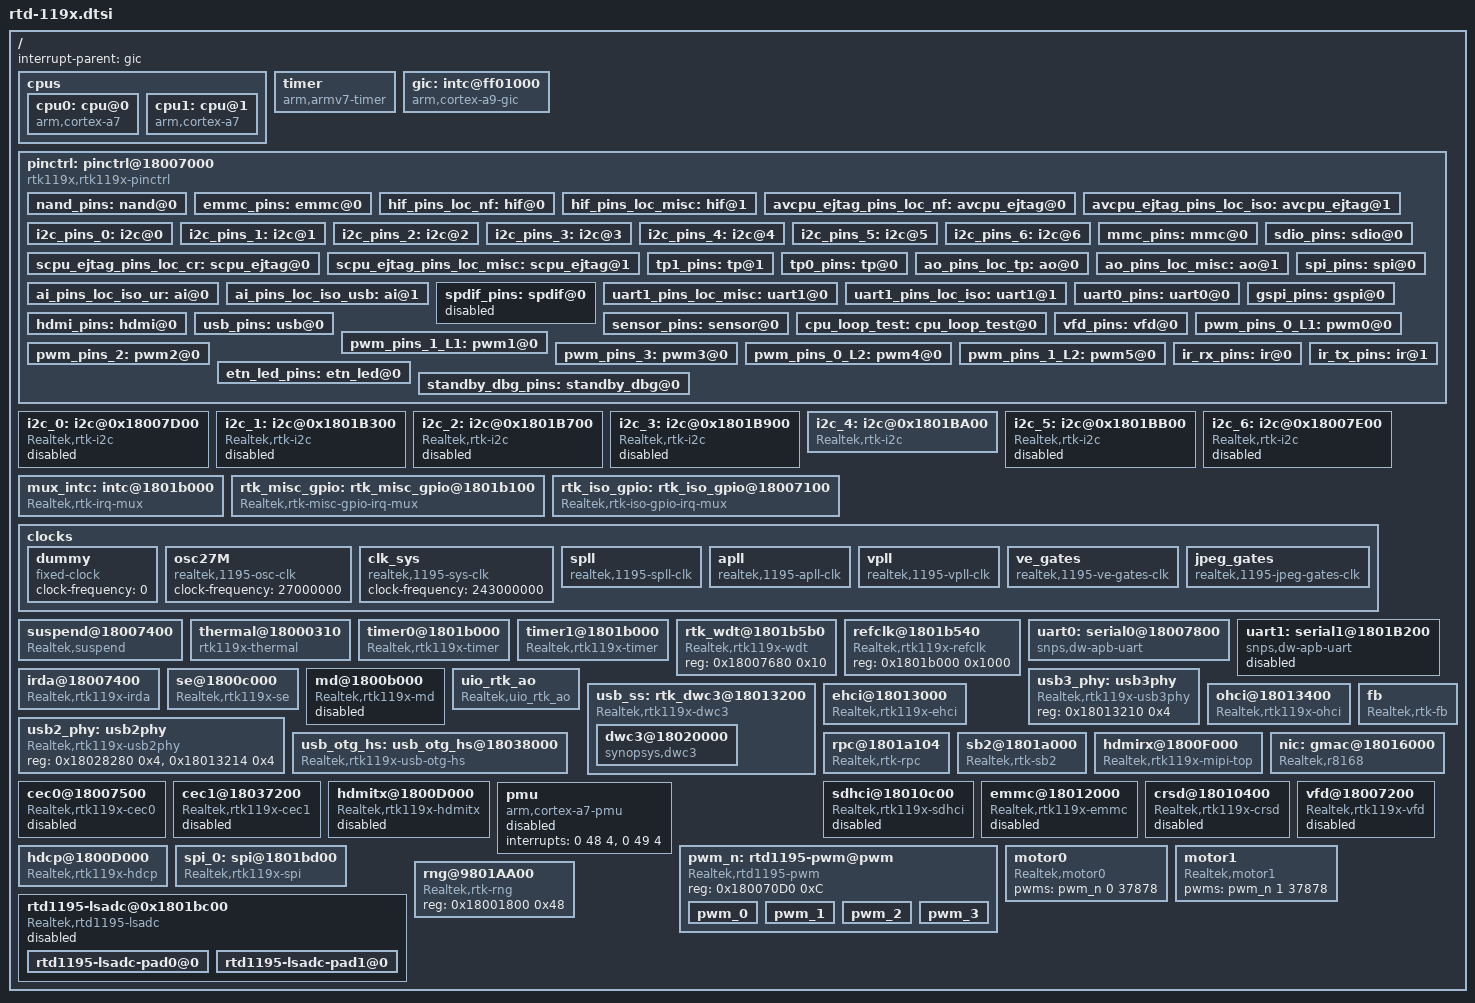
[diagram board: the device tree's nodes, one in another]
/include/ "skeleton.dtsi"
/include/ "rtd-119x-dvfs.dtsi"


/ {
	interrupt-parent = <&gic>;
	#address-cells = <1>;
	#size-cells = <1>;

	cpus {
		#address-cells = <1>;
		#size-cells = <0>;

		cpu0: cpu@0 {
			device_type = "cpu";
			compatible = "arm,cortex-a7";
			reg = <0x0>;
			clock-frequency = <1000000000>;
		};
		cpu1: cpu@1 {
			device_type = "cpu";
			compatible = "arm,cortex-a7";
			reg = <0x1>;
			clock-frequency = <1000000000>;
		};
	};
	timer {
		compatible = "arm,armv7-timer";
		interrupts = <1 13 0xf08>,			/* secure */
			     <1 14 0xf08>;				/* non-secure */
//			     <1 11 0xf08>,				/* virtual */
//			     <1 10 0xf08>;				/* hypervisor */
		clock-frequency = <27000000>;
	};
	gic: intc@ff01000 {
		compatible = "arm,cortex-a9-gic";
		#interrupt-cells = <3>;
		interrupt-controller;
		reg = <0xff011000 0x1000>,
		      <0xff012000 0x1000>;
	};

	pinctrl: pinctrl@18007000 {
		compatible = "rtk119x,rtk119x-pinctrl";
		reg = <0x018000000 0x500>, <0x18007000 0x400>;
		#gpio-range-cells = <3>;

		pinctrl-names = "default";
		pinctrl-0 = <&uart1_pins_loc_iso>,<&mmc_pins>,<&pwm_pins_0_L2>,<&pwm_pins_1_L2>,<&i2c_pins_4>;

		nand_pins: nand@0 {
			rtk119x,pins =
			"nf_dd_0", 	"nf_dd_1",	"nf_dd_2", 	"nf_dd_3",	"nf_dd_4", 	"nf_dd_5",
			"nf_dd_6", 	"nf_dd_7",	"nf_rdy", 		"nf_rd_n",	"nf_wr_n", 	"nf_ale",
			"nf_cle", 		"nf_ce_n_0",	"nf_ce_n_1", 	"i2c_scl_5",	"i2c_sda_5";
			rtk119x,function = "nand";
			rtk119x,pull_en = <0>;
		};
		emmc_pins: emmc@0 {
			rtk119x,pins=
			"nf_dd_0", 	"nf_dd_1",	"nf_dd_2", 	"nf_dd_3",	"nf_dd_4", 	"nf_dd_5",
			"nf_dd_6", 	"nf_dd_7",	"nf_rdy", 		"nf_rd_n",	"nf_cle";
			rtk119x,function = "emmc";
			rtk119x,pull_en = <0>;
		};
		hif_pins_loc_nf: hif@0 {
			rtk119x,pins =
			"nf_dd_4", 	"nf_wr_n",	"nf_ale", 		"nf_cle", 		"hi_loc";
			rtk119x,function = "hif_loc_nf";
			rtk119x,pull_en = <0>;
		};
		hif_pins_loc_misc: hif@1 {
			rtk119x,pins =
			"gpio_0", 	"gpio_1"	,	"gpio_2", 	"gpio_3", 	"hi_loc",	"sf_en";
			rtk119x,function = "hif_loc_misc";
			rtk119x,pull_en = <0>;
		};
		avcpu_ejtag_pins_loc_nf: avcpu_ejtag@0 {
			rtk119x,pins =
			"nf_dd_5", 	"nf_dd_6",	"nf_dd_7", 	"nf_rdy",		"nf_rd_n",	"ejtag_avcpu_loc";
			rtk119x,function = "avcpu_ejtag_loc_nf";
			rtk119x,pull_en = <0>;
		};
		avcpu_ejtag_pins_loc_iso: avcpu_ejtag@1 {
			rtk119x,pins =
			"usb0", 		"usb1",		"vfd_cs_n", 	"vfd_clk",		"vfd_d",		"ejtag_avcpu_loc";
			rtk119x,function = "avcpu_ejtag_loc_iso";
			rtk119x,pull_en = <0>;
		};
		i2c_pins_0: i2c@0 {
			rtk119x,pins =
			"i2c_scl_0", "i2c_sda_0";
			rtk119x,function = "i2c0";
			rtk119x,pull_en = <0>;

//			rtk119x,schmitt = <1>;		//0: schmitt_disable, 1:schmitt_enable
//			rtk119x,drive = <4>;		//drive current : 2=2mA  4=4mA 8=8mA
//			rtk119x,pull_en = <1>;		//0: pull_disable, 1:pull_enable
//			rtk119x,pull_sel = <1>;		//0: pull_low, 1:pull_high
		};
		i2c_pins_1: i2c@1 {
			rtk119x,pins =
			"i2c_scl_1", 	"i2c_sda_1";
			rtk119x,function = "i2c1";
			rtk119x,pull_en = <0>;
		};
		i2c_pins_2: i2c@2 {
			rtk119x,pins =
			"tp1_clk",		"tp1_sync",	"vfd_d";
			rtk119x,function = "i2c2";
			rtk119x,pull_en = <0>;
		};
		i2c_pins_3: i2c@3 {
			rtk119x,pins =
			"tp1_data", 	"tp1_valid";
			rtk119x,function = "i2c3";
			rtk119x,pull_en = <0>;
		};
		i2c_pins_4: i2c@4 {
			rtk119x,pins =
			"i2c_scl_4", 	"i2c_sda_4";
			rtk119x,function = "i2c4";
			rtk119x,pull_en = <0>;
		};
		i2c_pins_5: i2c@5 {
			rtk119x,pins =
			"i2c_scl_5",	"i2c_sda_5";
			rtk119x,function = "i2c5";
			rtk119x,pull_en = <0>;

//			rtk119x,schmitt = <1>;		//0: schmitt_disable, 1:schmitt_enable
//			rtk119x,drive = <2>;		//drive current : 2=2mA  4=4mA 8=8mA
//			rtk119x,pull_en = <1>;		//0: pull_disable, 1:pull_enable
//			rtk119x,pull_sel = <1>;		//0: pull_low, 1:pull_high
		};
		i2c_pins_6: i2c@6 {
			rtk119x,pins =
			"i2c_scl_6",	"i2c_sda_6";
			rtk119x,function = "i2c6";
			rtk119x,pull_en = <0>;
		};
		mmc_pins: mmc@0 {
			rtk119x,pins =
			"mmc_data_0", 	"mmc_data_1",	"mmc_data_2", 	"mmc_data_3",	"mmc_clk", 	"mmc_cmd",
			"mmc_wp", 		"mmc_cd";
			rtk119x,function = "mmc";
			rtk119x,pull_en = <0>;
		};
		scpu_ejtag_pins_loc_cr: scpu_ejtag@0 {
			rtk119x,pins =
			"mmc_data_0", 	"mmc_data_3",	"mmc_clk", 	"mmc_cmd",	"mmc_wp",	"ejtag_scpu_loc";
			rtk119x,function = "scpu_ejtag_loc_cr";
			rtk119x,pull_en = <0>;
		};
		scpu_ejtag_pins_loc_misc: scpu_ejtag@1 {
			rtk119x,pins =
			"gpio_4", 		"gpio_5",			"gpio_6", 	"gpio_7",		"gpio_8",		"ejtag_scpu_loc";
			rtk119x,function = "scpu_ejtag_loc_misc";
			rtk119x,pull_en = <0>;
		};
		sdio_pins: sdio@0 {
			rtk119x,pins =
			"sdio_clk", 	"sdio_data_0",		"sdio_data_1", 	"sdio_data_2",		"sdio_data_3", 	"sdio_cmd";
			rtk119x,function = "sdio";
			rtk119x,pull_en = <0>;
		};
		tp1_pins: tp@1 {
			rtk119x,pins =
			"tp1_data", 	"tp1_clk",		"tp1_valid", 	"tp1_sync";
			rtk119x,function = "tp1";
			rtk119x,pull_en = <0>;
		};
		tp0_pins: tp@0 {
			rtk119x,pins =
			"tp0_data", 	"tp0_clk",		"tp0_valid", 	"tp0_sync";
			rtk119x,function = "tp0";
			rtk119x,pull_en = <0>;
		};
		ao_pins_loc_tp: ao@0 {
			rtk119x,pins =
			"tp0_data", 	"tp0_clk",		"tp0_valid", 	"tp0_sync",	"ao_loc";
			rtk119x,function = "ao_loc_tp";
			rtk119x,pull_en = <0>;
		};
		ao_pins_loc_misc: ao@1 {
			rtk119x,pins =
			"gpio_4", 	"gpio_5",		"gpio_6", 	"gpio_7",		"ao_loc";
			rtk119x,function = "ao_loc_misc";
			rtk119x,pull_en = <0>;
		};
		ai_pins_loc_iso_ur: ai@0 {
			rtk119x,pins =
			"ur1_rx", 	"ur1_tx",		"ur1_cts_n", 	"ur1_rts_n",	"ai_loc";
			rtk119x,function = "ai_loc_iso_ur";
			rtk119x,pull_en = <0>;
		};
		ai_pins_loc_iso_usb: ai@1 {
			rtk119x,pins =
			"usb0", 		"usb1",		"vfd_cs_n", 	"vfd_clk",		"ai_loc";
			rtk119x,function = "ai_loc_iso_usb";
			rtk119x,pull_en = <0>;
		};

		spdif_pins: spdif@0 {
			rtk119x,pins =
			"spdif";
			rtk119x,function = "spdif";
			rtk119x,pull_en = <0>;
			status = "disabled";
		};
		spi_pins: spi@0 {
			rtk119x,pins =
			"gpio_0", 	"gpio_1"	,	"gpio_2", 	"gpio_3",		"sf_en";
			rtk119x,function = "spi";
			rtk119x,pull_en = <0>;
		};
		uart1_pins_loc_misc: uart1@0 {
			rtk119x,pins =
			"gpio_0", 	"gpio_1"	,	"gpio_2", 	"gpio_3",		"ur1_loc",	"sf_en";
			rtk119x,function = "uart1_loc_misc";
			rtk119x,pull_en = <0>;
		};
		uart1_pins_loc_iso: uart1@1 {
			rtk119x,pins =
			"ur1_rx", 	"ur1_tx",		"ur1_cts_n", 	"ur1_rts_n",	"ur1_loc";
			rtk119x,function = "uart1_loc_iso";
			rtk119x,pull_en = <0>;
		};
		uart0_pins: uart0@0 {
			rtk119x,pins =
			"ur0_rx", 	"ur0_tx";
			rtk119x,function = "uart0";
			rtk119x,pull_en = <0>;
		};
		gspi_pins: gspi@0 {
			rtk119x,pins =
			"gpio_0", 	"gpio_1"	,	"gpio_2", 	"gpio_3",		"sf_en";
			rtk119x,function = "gspi";
			rtk119x,pull_en = <0>;
		};
		hdmi_pins: hdmi@0 {
			rtk119x,pins =
			"hdmi_hpd";
			rtk119x,function = "hdmi";
			rtk119x,pull_en = <0>;
		};
		usb_pins: usb@0 {
			rtk119x,pins=
			"usb_id";
			rtk119x,function = "usb";
			rtk119x,pull_en = <0>;
		};
		sensor_pins: sensor@0 {
			rtk119x,pins =
			"sensor_cko_0", 	"sensor_cko_",	"sensor_rst", 		"sensor_stb_0",	"sensor_stb_1";
			rtk119x,function = "sensor";
			rtk119x,pull_en = <0>;
		};
		cpu_loop_test: cpu_loop_test@0 {
			rtk119x,pins=
			"usb_id";
			rtk119x,function = "cpu_loop";
			rtk119x,pull_en = <0>;
		};
		vfd_pins: vfd@0 {
			rtk119x,pins =
			"vfd_cs_n", 	"vfd_clk",		"vfd_d";
			rtk119x,function = "vfd";
			rtk119x,pull_en = <0>;
		};
		pwm_pins_0_L1: pwm0@0 {
			rtk119x,pins =
			"ur1_rx";
			rtk119x,function = "pwm";
			rtk119x,pull_en = <0>;
		};
		pwm_pins_1_L1: pwm1@0 {
			rtk119x,pins =
			"ur1_tx";
			rtk119x,function = "pwm";
			rtk119x,pull_en = <0>;
		};
		pwm_pins_2: pwm2@0 {
			rtk119x,pins =
			"ur0_tx";
			rtk119x,function = "pwm";
			rtk119x,pull_en = <0>;
		};
		pwm_pins_3: pwm3@0 {
			rtk119x,pins =
			"ur0_rx";
			rtk119x,function = "pwm";
			rtk119x,pull_en = <0>;
		};
		pwm_pins_0_L2: pwm4@0 {
			rtk119x,pins =
			"etn_led_link";
			rtk119x,function = "pwm";
			rtk119x,pull_en = <0>;
		};
		pwm_pins_1_L2: pwm5@0 {
			rtk119x,pins =
			"etn_led_rxtx";
			rtk119x,function = "pwm";
			rtk119x,pull_en = <0>;
		};
		ir_rx_pins: ir@0 {
			rtk119x,pins =
			"ir_rx";
			rtk119x,function = "irrx";
			rtk119x,pull_en = <0>;
		};
		ir_tx_pins: ir@1 {
			rtk119x,pins =
			"ir_tx";
			rtk119x,function = "irtx";
			rtk119x,pull_en = <0>;
		};
		etn_led_pins: etn_led@0 {
			rtk119x,pins =
			"etn_led_link", 	"etn_led_rxtx";
			rtk119x,function = "etn_led";
			rtk119x,pull_en = <0>;
		};
		standby_dbg_pins: standby_dbg@0 {
			rtk119x,pins =
			"usb0",	"usb1",   "ir_rx";
			rtk119x,function = "standby_dbg";
			rtk119x,pull_en = <0>;
		};
	};

i2c_0: i2c@0x18007D00 {
		compatible = "Realtek,rtk-i2c";
		reg = <0x18007D00 0x400>;
		interrupt-parent = <&mux_intc>;
		interrupts = <1 8>;
		i2c-num = <0>;
		#address-cells = <1>;
		#size-cells = <0>;
		status = "dis";
	};
	i2c_1: i2c@0x1801B300 {
		compatible = "Realtek,rtk-i2c";
		reg = <0x1801B300 0x400>;
		interrupt-parent = <&mux_intc>;
		interrupts = <0 4>;
		i2c-num = <1>;
		#address-cells = <1>;
		#size-cells = <0>;
		status = "dis";
	};
	i2c_2: i2c@0x1801B700 {
		compatible = "Realtek,rtk-i2c";
		#address-cells = <1>;
		#size-cells = <0>;
		reg = <0x1801B700 0x400>;
		interrupt-parent = <&mux_intc>;
		interrupts = <0 26>;
		i2c-num = <2>;
		status = "dis";
	};
	i2c_3: i2c@0x1801B900 {
		compatible = "Realtek,rtk-i2c";
		reg = <0x1801B900 0x400>;
		interrupt-parent = <&mux_intc>;
		interrupts = <0 23>;
		i2c-num = <3>;
		#address-cells = <1>;
		#size-cells = <0>;
		status = "dis";
	};
	i2c_4: i2c@0x1801BA00 {
		compatible = "Realtek,rtk-i2c";
		reg = <0x1801BA00 0x400>;
		interrupt-parent = <&mux_intc>;
		interrupts = <0 15>;
		i2c-num = <4>;
		#address-cells = <1>;
		#size-cells = <0>;
	};
	i2c_5: i2c@0x1801BB00 {
		compatible = "Realtek,rtk-i2c";
		reg = <0x1801BB00 0x400>;
		interrupt-parent = <&mux_intc>;
		interrupts = <0 14>;
		i2c-num = <5>;
		#address-cells = <1>;
		#size-cells = <0>;
		status = "dis";
	};
	i2c_6: i2c@0x18007E00 {
		compatible = "Realtek,rtk-i2c";
		reg = <0x18007E00 0x400>;
		interrupt-parent = <&mux_intc>;
		interrupts = <1 10>;
		i2c-num = <6>;
		#address-cells = <1>;
		#size-cells = <0>;
		status = "dis";
	};

	mux_intc: intc@1801b000 {
		compatible = "Realtek,rtk-irq-mux";
		Realtek,mux-nr = <2>;
		#interrupt-cells = <2>;
		interrupt-controller;
		reg = <0x1801b000 0x100>, <0x18007000 0x100>;		/* MISC_TOP MISC_ISO */
		interrupts = <0 40 4>, <0 41 4>;
		intr-status = <0xc>, <0x0>;
		intr-en = <0x80>, <0x40>;
	};

	rtk_misc_gpio: rtk_misc_gpio@1801b100 {
		compatible = "Realtek,rtk-misc-gpio-irq-mux";
		gpio-controller;
		#gpio-cells = <3>;								/*must be the same with gpiochip.of_gpio_n_cells*/
		Realtek,gpio_base = <0>;
		Realtek,gpio_numbers = <60>;
		interrupt-parent = <&mux_intc>;
		#interrupt-cells = <1>;
		interrupt-controller;
		interrupts = <0 19>, <0 20>;						/*GPIOA_INT   GPIODA_INT*/
		reg = <0x1801b000 0x100>, <0x1801b100 0x100>;		/* MISC_SYS MISC_GPIO*/
		gpio-ranges = <&pinctrl 0 0 60>;
	};


	rtk_iso_gpio: rtk_iso_gpio@18007100 {
		compatible = "Realtek,rtk-iso-gpio-irq-mux";
		gpio-controller;
		#gpio-cells = <3>;
		Realtek,gpio_base = <60>;
		Realtek,gpio_numbers = <21>;
		interrupt-parent = <&mux_intc>;
		#interrupt-cells = <1>;
		interrupt-controller;
		interrupts = <1 19>, <1 20>;						/*GPIOA_INT   GPIODA_INT*/
		reg = <0x18007000 0x100>, <0x18007100 0x100>;		/* ISO_SYS ISO_GPIO*/
		gpio-ranges = <&pinctrl 0 64 21>;
	};

	clocks {
		#address-cells = <1>;
		#size-cells = <1>;
		ranges;

		/*
		 * This is a dummy clock, to be used as placeholder on
		 * other mux clocks when a specific parent clock is not
		 * yet implemented. It should be dropped when the driver
		 * is complete.
		 */
		dummy: dummy {
			compatible = "fixed-clock";
			#clock-cells = <0>;
			clock-frequency = <0>;
		};

		//osc33m: osc33m {
		//	compatible = "fixed-clock";
		//	#clock-cells = <0>;
		//	clock-frequency = <33000000>;
		//};

        osc27M: osc27M {
            compatible = "realtek,1195-osc-clk";
            #clock-cells = <0>;
            clock-frequency = <27000000>;
        };

        clk_sys: clk_sys {
            compatible = "realtek,1195-sys-clk";
            #clock-cells = <0>;
            clock-frequency = <243000000>;
        };

        spll: spll { // freq = osc * (n + 1 + f/2048) / (0x1 << d)
            compatible = "realtek,1195-spll-clk";
            #clock-cells = <0>;
            clocks      = <&osc27M>;
            reg         = <0x18000000 0x134>;
            //n-max        = <>;
            n-min        = <0>;
            //f-max        = <>;
            f-min        = <0>;
            //d-max        = <0>;
            d-min        = <0>;
            pll-max-frequency = <3000000000>; // 3GHz
            pll-min-frequency = <200000000>; // 200MHz
            clock-names = "scpu";
        };

        apll: apll { // freq = osc * (n + 2) / (f + 1) / (d + 1)
            compatible = "realtek,1195-apll-clk";
            #clock-cells = <0>;
            clocks       = <&osc27M>;
            reg          = <0x1800010c 0x8>;
            //n-max        = <>;
            n-min        = <0>;
            //f-max        = <0>;
            f-min        = <0>;
            d-max        = <0>;
            d-min        = <0>;
            pll-max-frequency = <1000000000>; // 1GHz
            pll-min-frequency = <50000000>; // 50MHz
            clock-names = "acpu";
        };

        vpll: vpll { // freq = osc * (n + 2) / (f + 1) / (d + 1)
            compatible = "realtek,1195-vpll-clk";
            #clock-cells = <0>;
            clocks       = <&osc27M>;
            reg          = <0x18000114 0x8>;
            //n-max        = <>;
            n-min        = <0>;
            f-max        = <0>;
            f-min        = <0>;
            //d-max        = <0>;
            d-min        = <0>;
            pll-max-frequency = <1000000000>; // 1GHz
            pll-min-frequency = <0>;
            clock-names = "ve";
        };

        ve_gates: ve_gates {
            #clock-cells = <1>;
            compatible = "realtek,1195-ve-gates-clk";
            reg = <0x1800000c 0x4>;
            clocks = <&vpll>;
            clock-output-names = "h265","h264";
        };

        jpeg_gates: jpeg_gates {
            compatible = "realtek,1195-jpeg-gates-clk";
            #clock-cells = <1>;
            reg = <0x1800000c 0x4>;
            clocks = <&clk_sys>;
            clock-output-names = "jpeg";
        };
	};

    suspend@18007400 {
        compatible = "Realtek,suspend";
        suspend-mode = <0>; // 0:SUSPEND_TO_RAM 1:SUSPEND_TO_COOLBOOT 2:SUSPEND_TO_WFI
        reg-restore = <0x18000000 0x18000004 0x18000008 0x1800000c 0x18000010>;
        reg-restore-size = <5>;
    };

    thermal@18000310 {
        compatible = "rtk119x-thermal";
        reg = <0x180171C8 0x4>, <0x18000310 0x4>, <0x18000314 0x4>;
        thermal0-disable = <0>;
        thermal1-disable = <0>;
        thermal-polling-ms = <500>;
        thermal-trip-shutdown = <0>;
        thermal-trend-urgent = <0>;
        thermal-table = <
            105     800000
            >; // temperature(degree Celsius) frequency(kHz)

        status = "okay";
    };

	timer0@1801b000 {
		compatible = "Realtek,rtk119x-timer";
		reg = <0x1801b000 0x600>;
		interrupts = <0 17 4>;
		/* This value must be overriden by the board. */
		clock-frequency = <0>;
	};
	timer1@1801b000 {
		compatible = "Realtek,rtk119x-timer";
		reg = <0x1801b000 0x600>;
		interrupts = <0 18 4>;
		/* This value must be overriden by the board. */
		clock-frequency = <0>;
	};
	rtk_wdt@1801b5b0 {
		compatible = "Realtek,rtk119x-wdt";
		reg = <0x18007680 0x10>;
	};

    refclk@1801b540 {
        compatible = "Realtek,rtk119x-refclk";
        reg = <0x1801b000 0x1000>;
    };

	uart0: serial0@18007800 {
		compatible = "snps,dw-apb-uart";
		interrupt-parent = <&mux_intc>;
		reg = <0x18007800 0x400>, <0x18007000 0x100>;
        interrupts-st-mask = <0x4>;
		interrupts = <1 2>;
		reg-shift = <2>;
		reg-io-width = <4>;
		/* This value must be overriden by the board. */
		clock-frequency = <0>;
	};
	uart1: serial1@1801B200 {
		compatible = "snps,dw-apb-uart";
		interrupt-parent = <&mux_intc>;
		reg = <0x1801B200 0x100>, <0x1801b00c 0x100>;
        interrupts-st-mask = <0x8>;
		interrupts = <0 3>, <0 5>;	/*UR1_INT and UR1_TO_INT*/
		reg-shift = <2>;
		reg-io-width = <4>;
		/* This value must be overriden by the board. */
		clock-frequency = <0>;
		status = "dis";
	};

	irda@18007400 {
		compatible = "Realtek,rtk119x-irda";
		interrupt-parent = <&mux_intc>;
		reg = <0x18007000 0x400>, <0x18007400 0x100>;
		interrupts = <1 5>;
//		pinctrl-names = "default";
//		pinctrl-0 = <&i2c_pins_5>;
//		status = "default";
//		gpios = <&rtk_iso_gpio 7>;
	};

	se@1800c000 {
		compatible = "Realtek,rtk119x-se";
		reg = <0x1800c000 0x600>;
		interrupts = <0 20 4>;
	};
	md@1800b000 {
		compatible = "Realtek,rtk119x-md";
		reg = <0x1800b000 0x100>;
		interrupts = <0 38 4>;
		status = "dis";
	};

	uio_rtk_ao {
		compatible = "Realtek,uio_rtk_ao";
		reg = <0x18000000 0x1000>, <0x18006000 0x1000>, <0x1800D000 0x1000>, <0x18071200 0x1000>;
	};

	usb_ss: rtk_dwc3@18013200 {
		compatible = "Realtek,rtk119x-dwc3";
		reg = <0x18013200 0x200>;
		interrupts = <0 21 4>;
		#address-cells = <1>;
		#size-cells = <1>;
		ranges;
		dwc3@18020000 {
			compatible = "synopsys,dwc3";
			reg = <0x18020000 0x9000>;
			interrupts = <0 21 4>;
			usb-phy = <&usb2_phy &usb3_phy>;
			dr_mode = "host";		/* peripheral */
//			tx-fifo-resize;
		};
	};
	usb3_phy: usb3phy {
		compatible = "Realtek,rtk119x-usb3phy";
		reg = <0x18013210 0x4>;
		#address-cells = <1>;
		#size-cells = <1>;
		ranges;
	};
	usb2_phy: usb2phy {
		compatible = "Realtek,rtk119x-usb2phy";
		reg = <0x18028280 0x4>, <0x18013214 0x4>;
		#address-cells = <1>;
		#size-cells = <1>;
		ranges;
	};
	ehci@18013000 {
		compatible = "Realtek,rtk119x-ehci";
		reg = <0x18013000 0x400>;
		interrupts = <0 21 4>;
	};
	ohci@18013400 {
		compatible = "Realtek,rtk119x-ohci";
		reg = <0x18013400 0x400>;
		interrupts = <0 21 4>;
	};
	usb_otg_hs: usb_otg_hs@18038000 {
		compatible = "Realtek,rtk119x-usb-otg-hs";
		reg = <0x18038000 0x8000>;
		interrupts = <0 21 4>;
	};

	fb {
		compatible = "Realtek,rtk-fb";
		reg = <0x1E800000 0x1800000>;
		resolution = <1280 720>;
		fps = <60>;
	};
	rpc@1801a104 {
		compatible = "Realtek,rtk-rpc";
		reg = <0x1801a104 0xc>;
		interrupts = <0 33 4>;
	};
	sb2@1801a000 {
		compatible = "Realtek,rtk-sb2";
		reg = <0x1801a000 0x900>;
		interrupts = <0 36 4>;
	};
	hdmirx@1800F000 {
		compatible = "Realtek,rtk119x-mipi-top";
		reg = <0x1800F000 0x418>,<0x1800FB00 0x100>,<0x18037200 0xDC>,<0x18037300 0x14>,<0x1800F600 0x1c>,<0x18037400 0x40>,<0x1800F000 0x200>,<0x1800F200 0x60>,<0x1800F260 0xA0>,<0x1800F300 0xC0>,<0x1800F3C0 0x20>,<0x1800F3E0 0x10>,<0x1800d1b0 0x10>,<0x18037700 0x98>,<0x18037600 0x98>,<0x18004100 0x100>,<0x18004000 0xf0>,<0x1800FF00 0x28>, <0x1800FD00 0x50>;
		interrupts = <0 23 4>;
		mipi_input_type = <0>;/* 0:camera in ;1:HDMI_RX in */
		mipi_camera_type = <5>; /* 1:MIPI_CAMERA_RLE0551C; 2:MIPI_CAMERA_RTS5845; 3:MIPI_CAMERA_OV5645 4:MIPI_CAMERA_OV5647 5:MIPI_CAMERA_OV9782*/
		power-saving = <0>; /* 1:ON,0:OFF; Turn off RX when cable unplugged */
	};
	nic: gmac@18016000 {
		compatible = "Realtek,r8168";
		reg = <0x18016000 0x1000>;
		interrupts = <0 22 4>;
		rtl-config = <1>;
		mac-version = <42>;		/* RTL_GIGA_MAC_VER_42 */
		rtl-features = <2>;		/* BIT(2) GMii */
	};
	cec0@18007500 {
		compatible = "Realtek,rtk119x-cec0";
		interrupt-parent = <&mux_intc>;
		reg = <0x18007500 0xe0>,<0x18007040 0xa>;
		interrupts = <1 22>;
		module-enable = <0>;
		status = "disabled";
	};
	cec1@18037200 {
	    compatible = "Realtek,rtk119x-cec1";
	    reg = <0x18037200 0xf0>,<0x18007000 0xF00>,<0x18037500 0x10>;
		interrupts = <0 34 4>;
		module-enable = <1>;
	    status = "disabled";
    };
	hdmitx@1800D000 {
		compatible = "Realtek,rtk119x-hdmitx";
		reg = <0x1800d000 0x400>;
		gpios = <&rtk_iso_gpio 6 0 0>;          /*HPD, input, default N/A */
		interrupt-parent = <&rtk_iso_gpio>;
		interrupts = <6>;                       /*HPD*/
		status = "disabled";
	};
	sdhci@18010c00 {
		compatible = "Realtek,rtk119x-sdhci";
		reg = <0x18010c00 0x100>,<0x18000000 0x50>;
		interrupts = <0 45 4>;
		status = "dis";
	};
        emmc@18012000 {
                compatible = "Realtek,rtk119x-emmc";
                reg = <0x18012000 0x400>,<0x18000000 0x400>,<0x18010400 0x200>,<0x1801A000 0x80>,<0x18010C00 0x40>;     /*EMMC CRT CRSD BS2 SDIO */
                interrupts = <0 42 4>;
                speed-step = <0>;                               /* 0: sdr50, 1: ddr50, 2: hs200 */
		status = "dis";
        };
	crsd@18010400 {
		compatible = "Realtek,rtk119x-crsd";
		reg = <0x18000000 0x400>,<0x18010400 0x200>,<0x1801A000 0x80>,<0x18012000 0x10>,<0x18010C00 0x40>;	/*CRT CRSD BS2 EMMC SDIO */
		interrupts = <0 44 4>;
		status = "disabled";
	};
	pmu {
		compatible = "arm,cortex-a7-pmu";
		interrupts = <0 48 4>, <0 49 4>;
		status = "disabled";
	};
	vfd@18007200 {
		compatible = "Realtek,rtk119x-vfd";
		interrupt-parent = <&mux_intc>;
		reg = <0x18007000 0x100>, <0x18007200 0x100>;
		interrupts = <1 15>,<1 16>,<1 17>,<1 18>;
		status = "disabled";
	};
	hdcp@1800D000 {
		compatible = "Realtek,rtk119x-hdcp";
		reg = <0x1800d000 0x400>;
		interrupts = <0 31 4>;   /*gen Ri*/
	};
	spi_0: spi@1801bd00 {
		compatible = "Realtek,rtk119x-spi";
		reg = <0x1801bd00 40>;
		pinctrl-names = "default";
		pinctrl-0 = <&gspi_pins>;
		spi-cs-gpio = <&rtk_misc_gpio 2 1 1>;
		status = "okay";
	};
	pwm_n: rtd1195-pwm@pwm {
		compatible = "Realtek,rtd1195-pwm";
		#pwm-cells = <2>;
		reg = <0x180070D0 0xC>;
		status = "okay";
        	pwm_0 {
            		enable = <1>;
            		clkout_div = <0xff>; //default OCD: from 0x0 to 0xff
            		clksrc_div = <0x1>;  //default OSD: from 0x0 to 0xf
            		duty_rate = <0>;  //default duty_rate 0 ~ 100
        	};
        	pwm_1 {
            		enable = <1>;
            		clkout_div = <0xff>; //default OCD: from 0x0 to 0xff
            		clksrc_div = <0x1>;  //default OSD: from 0x0 to 0xf
            		duty_rate = <0>;  //default duty_rate 0 ~ 100
        	};
        	pwm_2 {
            		enable = <0>;
            		clkout_div = <0xff>; //default OCD: from 0x0 to 0xff
            		clksrc_div = <0x1>;  //default OSD: from 0x0 to 0xf
            		duty_rate = <50>;  //default duty_rate 0 ~ 100
        	};
        	pwm_3 {
            		enable = <0>;
            		clkout_div = <0xff>; //default OCD: from 0x0 to 0xff
            		clksrc_div = <0x1>;  //default OSD: from 0x0 to 0xf
            		duty_rate = <50>;  //default duty_rate 0 ~ 100
        	};

	};
	motor0 {
		compatible = "Realtek,motor0";
		status = "okay";
		pwms = <&pwm_n 0 37878>;
	};
	motor1 {
		compatible = "Realtek,motor1";
		status = "okay";
		pwms = <&pwm_n 1 37878>;
	};
	rtd1195-lsadc@0x1801bc00 {
		compatible = "Realtek,rtd1195-lsadc";
		interrupt-parent = <&mux_intc>;
		interrupts = <0 21>;
		status = "disabled";
		rtd1195-lsadc-pad0@0 {
			//compatible = "Realtek,rtd1195-lsadc-pad0";
			activate = 	<1>;			/* 0: in-activate; 1:activate */
			ctrl_mode = <0>; 			/* 0: Voltage mode; 1:Current mode*/
			sw_idx = 	<0>;			/* 0: External input pin 0; 1:External input pin 1 */
			voltage_threshold = <32>;	/* 8 bit : 0 ~ 255 */
		};
		rtd1195-lsadc-pad1@0 {
			//compatible = "Realtek,rtd1195-lsadc-pad1";
			activate = 	<1>;			/* 0: in-activate; 1:activate */
			ctrl_mode = <0>; 			/* 0: Voltage mode; 1:Current mode*/
			sw_idx = 	<0>;			/* 0: External input pin 0; 1:External input pin 1 */
			voltage_threshold = <16>;	/* 8 bit : 0 ~ 255 */
		};
	};

	rng@9801AA00 {
	        compatible = "Realtek,rtk-rng";
        	reg = <0x18001800 0x48>;
		status = "okay";

    	};

};
